VERSION ""

NS_ :

BS_:
BU_:
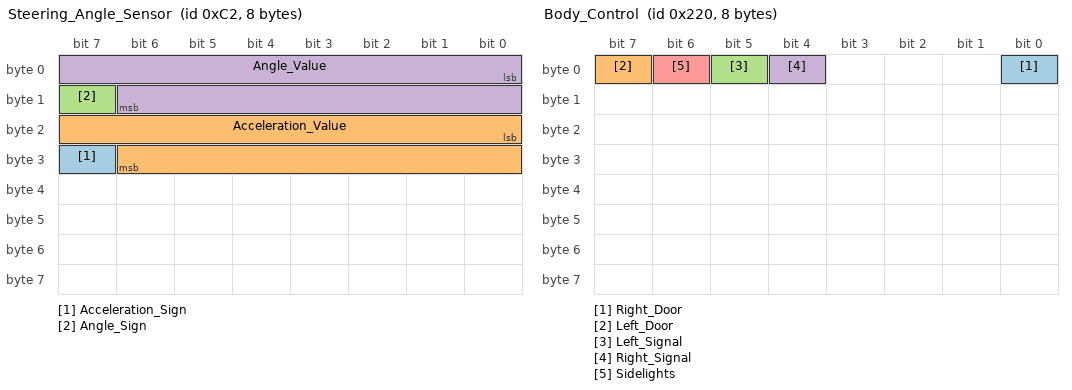
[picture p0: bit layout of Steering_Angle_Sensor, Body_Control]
BO_ 194 Steering_Angle_Sensor: 8 Vector__XXX
   SG_ Acceleration_Sign : 31|1@1+ (1,0) [0|0] "" Vector__XXX
   SG_ Acceleration_Value : 16|15@1+ (0.04375,0) [0|1433.6] "Degrees/Second" Vector__XXX
   SG_ Angle_Sign : 15|1@1+ (1,0) [0|0] "" Vector__XXX
   SG_ Angle_Value : 0|15@1+ (0.04375,0) [0|1433.6] "Degrees" Vector__XXX

BO_ 784 Throttle_Pedal: 8 Vector__XXX
   SG_ Throttle_position : 32|16@1+ (0.00156143,0) [0|0] "%" Vector__XXX

BO_ 544 Body_Control: 8 Vector__XXX
   SG_ Right_Door : 0|1@1+ (1,0) [0|0] "" Vector__XXX
   SG_ Left_Door : 7|1@1+ (1,0) [0|0] "" Vector__XXX
   SG_ Left_Signal : 5|1@1+ (1,0) [0|0] "" Vector__XXX
   SG_ Right_Signal : 4|1@1+ (1,0) [0|0] "" Vector__XXX
   SG_ Sidelights : 6|1@1+ (1,0) [0|0] "" Vector__XXX

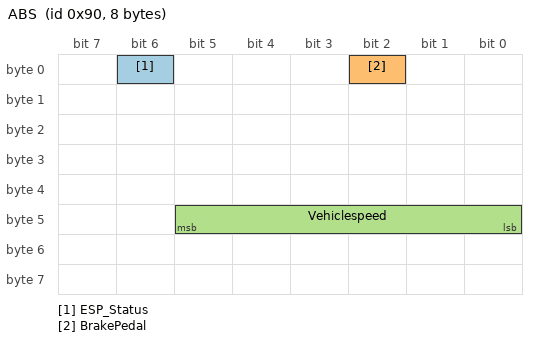
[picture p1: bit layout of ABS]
BO_ 144 ABS: 8 Vector__XXX
   SG_ ESP_Status : 6|1@1+ (1,0) [0|0] "" Vector__XXX
   SG_ BrakePedal : 2|1@1+ (1,0) [0|0] "" Vector__XXX
   SG_ Vehiclespeed : 45|6@0- (1,0) [0|0] "mph" Vector__XXX

BO_ 400 Gearbox: 8 Vector__XXX
   SG_ GearPosition : 0|8@1+ (1,0) [0|0] "" Vector__XXX

BO_ 520 Wheelspeeds: 8 Vector__XXX
   SG_ Wheelspeed_FR : 40|7@1- (1,0) [0|0] "mph" Vector__XXX
   SG_ Wheelspeed_FL : 48|7@1- (1,0) [0|0] "mph" Vector__XXX

BA_DEF_ BO_ "GenMsgBackgroundColor" STRING ;
BA_DEF_ BO_ "GenMsgForegroundColor" STRING ;
BA_DEF_DEF_ "GenMsgBackgroundColor" "#1e1e1e";
BA_DEF_DEF_ "GenMsgForegroundColor" "#ffffff";
VAL_ 544 Right_Door 0 "Open" 1 "Closed";
VAL_ 544 Left_Door 0 "Open" 1 "Closed";
VAL_ 544 Left_Signal 0 "Off" 1 "On";
VAL_ 544 Right_Signal 0 "Off" 1 "On";
VAL_ 544 Sidelights 0 "Off" 1 "On";
VAL_ 144 ESP_Status 0 "On" 1 "Off";
VAL_ 144 BrakePedal 0 "Not_pressed" 1 "Pressed";
VAL_ 400 GearPosition 8 "Neutral" 4 "Reverse" 76 "Auto" 16 "Manual";
